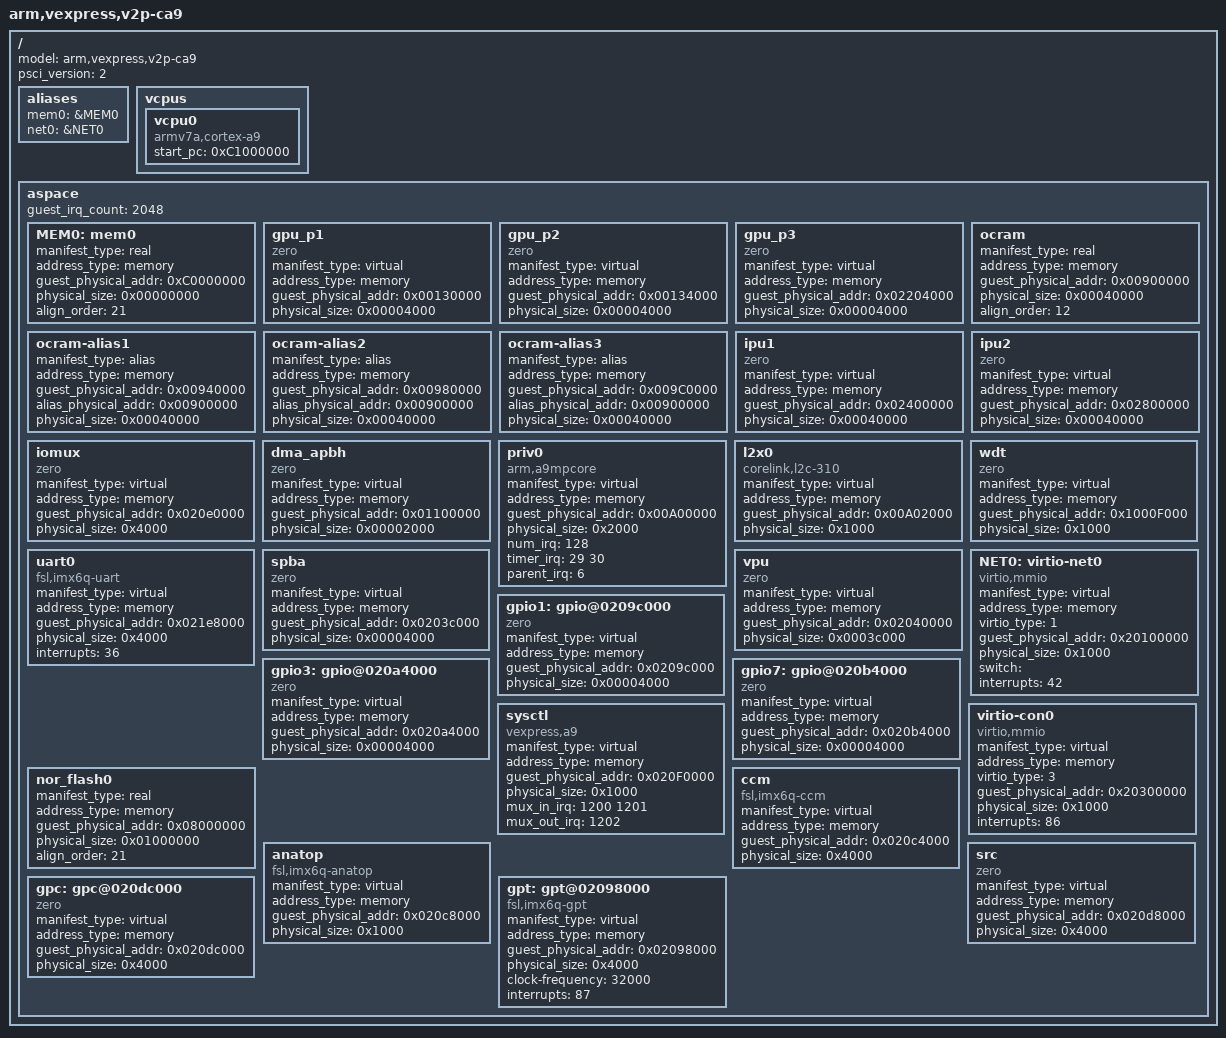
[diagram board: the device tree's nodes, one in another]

/dts-v1/;

/ {
	model = "arm,vexpress,v2p-ca9";
	device_type = "guest";
	psci_version = <2>;

	aliases {
		mem0 = &MEM0;
		net0 = &NET0;
	};

	vcpus {
		vcpu0 {
			device_type = "vcpu";
			compatible = "armv7a,cortex-a9";
			start_pc = <0xC1000000>;
		};

		/* vcpu1 { */
		/* 	device_type = "vcpu"; */
		/* 	compatible = "armv7a,cortex-a9"; */
		/* 	start_pc = <0xC1000000>; */
		/* }; */
	};

	aspace {
		guest_irq_count = <2048>;

		MEM0: mem0 {
			manifest_type = "real";
			address_type = "memory";
			guest_physical_addr = <0xC0000000>;
			physical_size = <0x00000000>; /* Override this before guest creation */
			align_order = <21>; /* Align alloced memory to 2MB */
			device_type = "alloced_ram";
		};

		gpu_p1 {
			manifest_type = "virtual";
			address_type = "memory";
			guest_physical_addr = <0x00130000>;
			physical_size = <0x00004000>;
			device_type = "misc";
			compatible = "zero";
		};

		gpu_p2 {
			manifest_type = "virtual";
			address_type = "memory";
			guest_physical_addr = <0x00134000>;
			physical_size = <0x00004000>;
			device_type = "misc";
			compatible = "zero";
		};

		gpu_p3 {
			manifest_type = "virtual";
			address_type = "memory";
			guest_physical_addr = <0x02204000>;
			physical_size = <0x00004000>;
			device_type = "misc";
			compatible = "zero";
		};

		ocram {
			manifest_type = "real";
			address_type = "memory";
			guest_physical_addr = <0x00900000>;
			physical_size = <0x00040000>;
			align_order = <12>; /* Align alloced memory to 4K */
			device_type = "alloced_ram";
		};

		ocram-alias1 {
			manifest_type = "alias";
			address_type = "memory";
			guest_physical_addr = <0x00940000>;
			alias_physical_addr = <0x00900000>;
			physical_size = <0x00040000>;
			device_type = "ram";
		};

		ocram-alias2 {
			manifest_type = "alias";
			address_type = "memory";
			guest_physical_addr = <0x00980000>;
			alias_physical_addr = <0x00900000>;
			physical_size = <0x00040000>;
			device_type = "ram";
		};

		ocram-alias3 {
			manifest_type = "alias";
			address_type = "memory";
			guest_physical_addr = <0x009C0000>;
			alias_physical_addr = <0x00900000>;
			physical_size = <0x00040000>;
			device_type = "ram";
		};

		ipu1 {
			manifest_type = "virtual";
			address_type = "memory";
			guest_physical_addr = <0x02400000>;
			physical_size = <0x00040000>;
			device_type = "misc";
			compatible = "zero";
		};

		ipu2 {
			manifest_type = "virtual";
			address_type = "memory";
			guest_physical_addr = <0x02800000>;
			physical_size = <0x00040000>;
			device_type = "misc";
			compatible = "zero";
		};

		iomux {
			manifest_type = "virtual";
			address_type = "memory";
			guest_physical_addr = <0x020e0000>;
			physical_size = <0x4000>;
			device_type = "misc";
			compatible = "zero";
		};

		dma_apbh {
			manifest_type = "virtual";
			address_type = "memory";
			guest_physical_addr = <0x01100000>;
			physical_size = <0x00002000>;
			device_type = "misc";
			compatible = "zero";
		};

		priv0 {
			manifest_type = "virtual";
			address_type = "memory";
			guest_physical_addr = <0x00A00000>;
			physical_size = <0x2000>;
			device_type = "misc";
			compatible = "arm,a9mpcore";
			num_irq = <128>;
			timer_irq = <29 30>;
			parent_irq = <6>;
		};

		l2x0 {
			manifest_type = "virtual";
			address_type = "memory";
			guest_physical_addr = <0x00A02000>;
			physical_size = <0x1000>;
			device_type = "cache";
			compatible = "corelink,l2c-310";
		};

		wdt { /* No Watch-Dog controller */
			manifest_type = "virtual";
			address_type = "memory";
			guest_physical_addr = <0x1000F000>;
			physical_size = <0x1000>;
			device_type = "misc";
			compatible = "zero";
		};

		uart0 {
			manifest_type = "virtual";
			address_type = "memory";
			guest_physical_addr = <0x021e8000>;
			physical_size = <0x4000>;
			device_type = "serial";
			compatible = "fsl,imx6q-uart", "fsl,imx21-uart";
			interrupts = <36>;
		};

		spba {
			manifest_type = "virtual";
			address_type = "memory";
			guest_physical_addr = <0x0203c000>;
			physical_size = <0x00004000>;
			device_type = "misc";
			compatible = "zero";
		};

		vpu {
			manifest_type = "virtual";
			address_type = "memory";
			guest_physical_addr = <0x02040000>;
			physical_size = <0x0003c000>;
			device_type = "misc";
			compatible = "zero";
		};

		/* /\* Emulate EPIT with a SP804 for now*\/ */
		/* timer0_1_legacy { */
		/* 	manifest_type = "virtual"; */
		/* 	address_type = "memory"; */
		/* 	guest_physical_addr = <0x020D0000>; */
		/* 	physical_size = <0x1000>; */
		/* 	device_type = "timer"; */
		/* 	compatible = "primecell,sp804"; */
		/* 	interrupts = <34>; */
		/* }; */

		/* epit1 { */
		/* 	manifest_type = "virtual"; */
		/* 	address_type = "memory"; */
		/* 	guest_physical_addr = <0x020d0000>; */
		/* 	physical_size = <0x1000>; */
		/* 	device_type = "misc"; */
		/* 	compatible = "zero"; */
		/* }; */

		/* timer2_3_legacy { */
		/* 	manifest_type = "virtual"; */
		/* 	address_type = "memory"; */
		/* 	guest_physical_addr = <0x10012000>; */
		/* 	physical_size = <0x1000>; */
		/* 	device_type = "timer"; */
		/* 	compatible = "primecell,sp804"; */
		/* 	interrupts = <35>; */
		/* }; */

		NET0: virtio-net0 {
			manifest_type = "virtual";
			address_type = "memory";
			device_type = "virtio";
			compatible = "virtio,mmio";
			virtio_type = <1>;
			guest_physical_addr = <0x20100000>;
			physical_size = <0x1000>;
			switch = ""; /* Override this before guest creation */
			interrupts = <42>;
		};

		gpio1: gpio@0209c000 {
			manifest_type = "virtual";
			address_type = "memory";
			guest_physical_addr = <0x0209c000>;
			physical_size = <0x00004000>;
			device_type = "misc";
			compatible = "zero";
		};

		gpio3: gpio@020a4000 {
			manifest_type = "virtual";
			address_type = "memory";
			guest_physical_addr = <0x020a4000>;
			physical_size = <0x00004000>;
			device_type = "misc";
			compatible = "zero";
		};

		gpio7: gpio@020b4000 {
			manifest_type = "virtual";
			address_type = "memory";
			guest_physical_addr = <0x020b4000>;
			physical_size = <0x00004000>;
			device_type = "misc";
			compatible = "zero";
		};

		virtio-con0 {
			manifest_type = "virtual";
			address_type = "memory";
			device_type = "virtio";
			compatible = "virtio,mmio";
			virtio_type = <3>;
			guest_physical_addr = <0x20300000>;
			physical_size = <0x1000>;
			interrupts = <86>;
		};

		nor_flash0 {
			manifest_type = "real";
			address_type = "memory";
			guest_physical_addr = <0x08000000>;
			physical_size = <0x01000000>;
			device_type = "alloced_rom";
			align_order = <21>; /* Align alloced memory to 2MB */
		};

		/* Use a reserved i.MX6 area to emulate VExpress-A9 sysctl */
		sysctl {
			manifest_type = "virtual";
			address_type = "memory";
			guest_physical_addr = <0x020F0000>;
			physical_size = <0x1000>;
			device_type = "sys";
			compatible = "vexpress,a9";
			mux_in_irq = <1200 1201>;
			mux_out_irq = <1202>;
		};

		ccm {
			manifest_type = "virtual";
			address_type = "memory";
			guest_physical_addr = <0x020c4000>;
			physical_size = <0x4000>;
			device_type = "misc";
			compatible = "fsl,imx6q-ccm";
		};

		anatop {
			manifest_type = "virtual";
			address_type = "memory";
			guest_physical_addr = <0x020c8000>;
			physical_size = <0x1000>;
			device_type = "misc";
			compatible = "fsl,imx6q-anatop";
		};

		src {
			manifest_type = "virtual";
			address_type = "memory";
			guest_physical_addr = <0x020d8000>;
			physical_size = <0x4000>;
			device_type = "misc";
			compatible = "zero";
		};

		gpc: gpc@020dc000 {
			manifest_type = "virtual";
			address_type = "memory";
			guest_physical_addr = <0x020dc000>;
			physical_size = <0x4000>;
			device_type = "misc";
			compatible = "zero";
		};

		gpt: gpt@02098000 {
			manifest_type = "virtual";
			address_type = "memory";
			guest_physical_addr = <0x02098000>;
			physical_size = <0x4000>;
			device_type = "timer";
			compatible = "fsl,imx6q-gpt";
			clock-frequency = <32000>;
			interrupts = <87>;
		};
	};
};
